# MSP430FR2476 register map
Vendor: msp430gen; File version: v0.4.0-28-gb0087ce-dirty
Registers are 16-bit, read-write, reset 0x0 unless marked. A register's access mark holds for its fields unless they carry their own. Offsets are from the block's base; [hi:lo] are bit positions; {n}, {i} and the like mark numbered series.

## ADC
Base 0x00000700
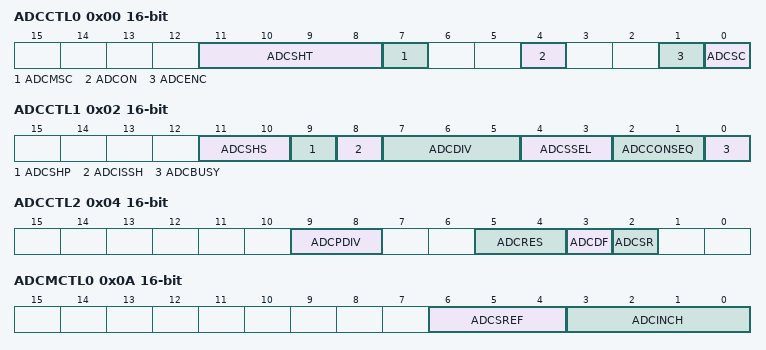
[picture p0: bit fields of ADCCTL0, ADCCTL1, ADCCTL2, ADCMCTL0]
0x00 ADCCTL0 — ADC Control 0
  [11:8] ADCSHT — sample-and-hold time.
    0=CYCLES_4 (4 ADCCLK cycles); 1=CYCLES_8 (8 ADCCLK cycles); 2=CYCLES_16 (16 ADCCLK cycles); 3=CYCLES_32 (32 ADCCLK cycles); 4=CYCLES_64 (64 ADCCLK cycles); 5=CYCLES_96 (96 ADCCLK cycles); 6=CYCLES_128 (128 ADCCLK cycles); 7=CYCLES_192 (192 ADCCLK cycles); 8=CYCLES_256 (256 ADCCLK cycles); 9=CYCLES_384 (384 ADCCLK cycles); 10=CYCLES_512 (512 ADCCLK cycles); 11=CYCLES_768 (768 ADCCLK cycles); 12=CYCLES_1024 (1024 ADCCLK cycles)
  [7] ADCMSC — sample-and-hold time.
    0=The sampling timer requires a rising edge of the SHI signal to trigger each sample-and-convert; 1=The incidence of a positive(or for devices first rising edge of the) SHI signal triggers the sampling timer, but further sample-and-conversions are performed automatically as soon as the prior conversion is completed
  [4] ADCON
    0=ADC off; 1=ADC on
  [1] ADCENC — enable conversion
    0=ADC disabled; 1=ADC enabled
  [0] ADCSC — start conversion
    0=No sample-and-conversion-start; 1=Start sample-and-conversion
0x02 ADCCTL1 — ADC Control 1
  [11:10] ADCSHS — sample-and-hold source select
    0=SOFTWARE (ADCSC bit (software trigger)); 1=RTC (RTC event); 2=TIMER (TA1.1B); 3=COMPARATOR (eCOMP0 COUT)
  [9] ADCSHP — sample-and-hold pulse-mode select
    0=SAMPCON signal is sourced from the sample-input signal; 1=SAMPCON signal is sourced from the sampling timer
  [8] ADCISSH — invert signal sample-and-hold
    0=The sample-input signal is not inverted; 1=The sample-input signal is inverted
  [7:5] ADCDIV — clock divider
    {v}=/{v+1} (Divide by {v+1}) (v=0..7)
  [4:3] ADCSSEL — clock source select
    0=MODCLK; 1=ACLK; 2=SMCLK
  [2:1] ADCCONSEQ — conversion sequence mode select
    0=SINGLE (Single-channel, single-conversion: a single channel is converted once); 1=SEQUENCE (Sequence-of-channels: a sequence of channels is converted once); 2=REPEAT_SINGLE (Repeat-single-channel: a single channel is converted repeatedly); 3=REPEAT_SEQUENCE (Repeat-sequence-of-channels: a sequence of channels is converted repeatedly)
  [0] ADCBUSY ro
    0=No operation is active; 1=A sequence, sample, or conversion is active
0x04 ADCCTL2 — ADC Control 2
  [9:8] ADCPDIV — ADC predivider. This bit predivides the selected ADC clock source before it gets divided again using ADCDIVx.
    0=/1 (Predivide by 1); 1=/4 (Predivide by 4); 2=/64 (Predivide by 64)
  [5:4] ADCRES — resolution
    0=BITS_8 (8 bit (10 clock cycle conversion time)); 1=BITS_10 (10 bit (12 clock cycle conversion time)); 2=BITS_12 (12 bit (14 clock cycle conversion time))
  [3] ADCDF — data read-back format
    0=UNSIGNED (Binary unsigned. Theoretically, the analog input voltage -VREF results in 0000h, and the analog input voltage +VREF results in 03FFh.); 1=SIGNED (Signed binary (2s complement), left aligned. Theoretically, the analog input voltage -VREF results in 8000h, and the analog input voltage +VREF results in 7FC0h.)
  [2] ADCSR — ADC sampling rate.
    0=MAX_200KSPS (ADC buffer supports up to approximately 200 ksps); 1=MAX_50KSPS (ADC buffer supports up to approximately 50 ksps)
0x06 ADCLO — ADC Window Comparator Low Threshold Register
0x08 ADCHI — ADC Window Comparator High Threshold Register
0x0A ADCMCTL0 — ADC Conversion Memory Control Register
  [6:4] ADCSREF — Select reference. It is not recommended to change this setting while a conversion is ongoing. Can be modified only when ADCENC = 0. Resetting ADCENC = 0 by software and changing these fields immediately shows an effect when a conversion is active.
    0=AVCC_AVSS (VR+ = AVCC and VR- = AVSS); 1=VREF_AVSS (VR+ = VREF and VR- = AVSS); 2=VEREF_PLUS_BUFFERED_AVSS (VR+ = VEREF+ buffered and VR- = AVSS); 3=VEREF_PLUS_AVSS (VR+ = VEREF+ and VR- = AVSS); 4=AVCC_VEREF_MINUS (VR+ = AVCC and VR- = VEREF-); 5=VREF_VEREF_MINUS (VR+ = VREF and VR- = VEREF-); 6=VEREF_PLUS_BUFFERED_VEREF_MINUS (VR+ = VEREF+ buffered and VR- = VEREF-); 7=VEREF_PLUS_VEREF_MINUS (VR+ = VEREF+ and VR- = VEREF-)
  [3:0] ADCINCH — Input channel select
    {v}=A{v} - see device-specific data sheet (v=0..5); 6=A2 - see device-specific data sheet; {v}=A{v} - see device-specific data sheet (v=7..15)
0x12 ADCMEM0 — ADC Conversion Memory Register
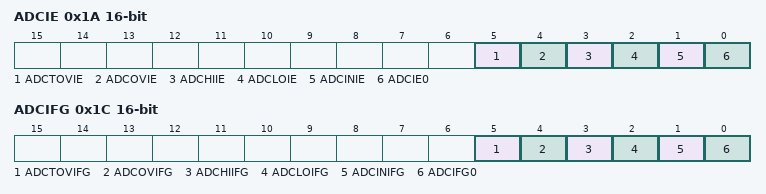
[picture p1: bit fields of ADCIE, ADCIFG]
0x1A ADCIE — ADC Interrupt Enable 0
  [5] ADCTOVIE — ADC conversion-time-overflow interrupt enable.
    0=0b = Conversion time overflow interrupt disabled; 1=1b = Conversion time overflow interrupt enabled
  [4] ADCOVIE — ADCMEM0 overflow interrupt enable.
    0=0b = Overflow interrupt disabled; 1=1b = Overflow interrupt enabled
  [3] ADCHIIE — Interrupt enable for the above upper threshold interrupt of the window comparator.
    0=0b = Above upper threshold interrupt disabled; 1=1b = Above upper threshold interrupt enabled
  [2] ADCLOIE — Interrupt enable for the below lower threshold interrupt of the window comparator.
    0=0b = Below lower threshold interrupt disabled; 1=1b = Below lower threshold interrupt enabled
  [1] ADCINIE — Interrupt enable for the inside of window interrupt of the window comparator.
    0=0b = Inside of window interrupt disabled; 1=1b = Inside of window interrupt enabled
  [0] ADCIE0 — Interrupt enable. This bits enable or disable the interrupt request for a completed ADC conversion.
    0=0b = Interrupt disabled; 1=1b = Interrupt enabled
0x1C ADCIFG — ADC Interrupt Flag
  [5] ADCTOVIFG — The ADCTOVIFG is set when an ADC conversion is triggered before the actual conversion has completed.
    0=ADCOVIFG_0 (No interrupt pending); 1=Interrupt pending
  [4] ADCOVIFG — The ADCOVIFG is set when the ADCMEM0 register is written before the last conversion result has been read.
    0=No interrupt pending; 1=Interrupt pending
  [3] ADCHIIFG — The ADCHIIFG is set when the result of the current ADC conversion is greater than the upper threshold defined by the window comparator upper threshold register.
    0=No interrupt pending; 1=Interrupt pending
  [2] ADCLOIFG — The ADCLOIFG is set when the result of the current ADC conversion is below the lower threshold defined by the window comparator lower threshold register.
    0=No interrupt pending; 1=Interrupt pending
  [1] ADCINIFG — The ADCINIFG is set when the result of the current ADC conversion is within the thresholds defined by the window comparator threshold registers.
    0=No interrupt pending; 1=Interrupt pending
  [0] ADCIFG0 — ADCMEM0 interrupt flag
    0=No interrupt pending; 1=Interrupt pending
0x1E ADCIV — ADC Interrupt Vector
  [15:0] ADCIV — interrupt vector value
    0=NONE (No interrupt pending); 2=OVERFLOW (Interrupt Source: ADCMEM0 overflow; Interrupt Flag: ADCOVIFG; Interrupt Priority: Highest); 4=TIME_OVERFLOW (Interrupt Source: Conversion time overflow; Interrupt Flag: ADCTOVIFG); 6=ABOVE_WINDOW (Interrupt Source: ADCHI Interrupt flag; Interrupt Flag: ADCHIIFG); 8=BELOW_WINDOW (Interrupt Source: ADCLO Interrupt flag; Interrupt Flag: ADCLOIFG); 10=INSIDE_WINDOW (Interrupt Source: ADCIN Interrupt flag; Interrupt Flag: ADCINIFG); 12=RESULT_READY (Interrupt Source: ADC memory Interrupt flag; Interrupt Flag: ADCIFG0; Interrupt Priority: Lowest)
